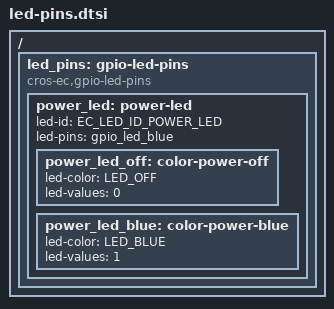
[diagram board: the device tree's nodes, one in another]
/* Copyright 2026 The ChromiumOS Authors
 * Use of this source code is governed by a BSD-style license that can be
 * found in the LICENSE file.
 */

/ {
	led_pins: gpio-led-pins {
		compatible = "cros-ec,gpio-led-pins";

		power_led: power-led {
			led-id = "EC_LED_ID_POWER_LED";
			led-pins = <&gpio_led_blue>;

			power_led_off: color-power-off {
				led-color = "LED_OFF";
				led-values = <0>;
			};

			power_led_blue: color-power-blue {
				led-color = "LED_BLUE";
				led-values = <1>;
			};
		};
	};
};
